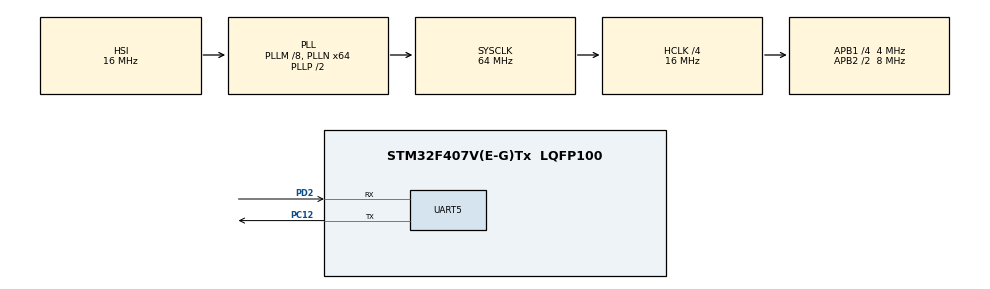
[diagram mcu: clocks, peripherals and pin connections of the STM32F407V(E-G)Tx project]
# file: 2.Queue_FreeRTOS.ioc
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Mcu.Family=STM32F4
Mcu.Name=STM32F407V(E-G)Tx
Mcu.Package=LQFP100
NVIC.PriorityGroup=NVIC_PRIORITYGROUP_4
NVIC.TIM6_DAC_IRQn=true\:15\:0\:false\:false\:true\:false\:true\:true
NVIC.TimeBase=TIM6_DAC_IRQn
NVIC.TimeBaseIP=TIM6
PA13.Mode=Serial_Wire
PA13.Signal=SYS_JTMS-SWDIO
PA14.Mode=Serial_Wire
PA14.Signal=SYS_JTCK-SWCLK
PC12.Mode=Asynchronous
PC12.Signal=UART5_TX
PD2.Mode=Asynchronous
PD2.Signal=UART5_RX
ProjectManager.HeapSize=0x200
ProjectManager.StackSize=0x400
ProjectManager.TargetToolchain=STM32CubeIDE
RCC.48MHZClocksFreq_Value=18285714.285714287
RCC.AHBCLKDivider=RCC_SYSCLK_DIV4
RCC.AHBFreq_Value=16000000
RCC.APB1CLKDivider=RCC_HCLK_DIV4
RCC.APB1Freq_Value=4000000
RCC.APB1TimFreq_Value=8000000
RCC.APB2CLKDivider=RCC_HCLK_DIV2
RCC.APB2Freq_Value=8000000
RCC.APB2TimFreq_Value=16000000
RCC.CortexFreq_Value=16000000
RCC.HCLKFreq_Value=16000000
RCC.HSE_VALUE=8000000
RCC.HSI_VALUE=16000000
RCC.LSE_VALUE=32768
RCC.PLLM=8
RCC.PLLN=64
RCC.PLLQ=7
RCC.SYSCLKFreq_VALUE=64000000
RCC.SYSCLKSource=RCC_SYSCLKSOURCE_PLLCLK
RCC.VCOOutputFreq_Value=128000000
UART5.VirtualMode=Asynchronous
VP_SYS_VS_tim6.Mode=TIM6
board=STM32F407G-DISC1

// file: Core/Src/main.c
/* USER CODE BEGIN Header */
/**
 ******************************************************************************
 * @file           : main.c
 * @brief          : Main program body
 ******************************************************************************
 * @attention
 *
 * Copyright (c) 2024 STMicroelectronics.
 * All rights reserved.
 *
 * This software is licensed under terms that can be found in the LICENSE file
 * in the root directory of this software component.
 * If no LICENSE file comes with this software, it is provided AS-IS.
 *
 ******************************************************************************
 */
/* USER CODE END Header */
#include "main.h"

/* USER CODE BEGIN Includes */

#include "FreeRTOS.h"
#include "task.h"
#include "queue.h"
#include<stdio.h>

/* USER CODE END Includes */

UART_HandleTypeDef huart5;

/* USER CODE BEGIN PV */

TaskHandle_t sender_handle, receiver_handle;
QueueHandle_t messageQueue;
QueueHandle_t numberQueue;

/* USER CODE END PV */

void SystemClock_Config(void);
static void MX_GPIO_Init(void);
static void MX_UART5_Init(void);
/* USER CODE BEGIN PFP */

void SenderTask(void *pvParameters);
void ReceiverTask(void *pvParameters);
int uart5_write(int ch);

/* USER CODE END PFP */

/* USER CODE BEGIN 0 */

// Sender task: sends messages to the queue
void SenderTask(void *pvParameters) {
	char *message1 = "Hello from Sender 1!\r\n";
	char *message2 = "Hello from Sender 2!\r\n";
	uint32_t data = 120;

	while (1) {
		xQueueSend(messageQueue, &message1, portMAX_DELAY); // Send message 1
		vTaskDelay(pdMS_TO_TICKS(500));                    // Wait 1 second

		xQueueSend(messageQueue, &message2, portMAX_DELAY); // Send message 2
		vTaskDelay(pdMS_TO_TICKS(500));                    // Wait 1 second

		xQueueSend(numberQueue, &data, portMAX_DELAY); // Send message 1
		vTaskDelay(pdMS_TO_TICKS(500));                    // Wait 1 second
	}
}

// Receiver task: receives messages from the queue and prints them using printf
void ReceiverTask(void *pvParameters) {
	char *receivedMessage;
	uint32_t data;
	while (1) {
		if (xQueueReceive(messageQueue, &receivedMessage,
				portMAX_DELAY) == pdPASS) {
			printf("%s", receivedMessage);  // Print received message via printf
		}

		if (xQueueReceive(numberQueue, &data, portMAX_DELAY) == pdPASS) {
			printf("Received : %lu\r\n", data); // Print received message via printf
		}
	}
}

/* USER CODE END 0 */

int main(void)
{

  /* MCU Configuration--------------------------------------------------------*/

  /* Reset of all peripherals, Initializes the Flash interface and the Systick. */
  HAL_Init();

  /* Configure the system clock */
  SystemClock_Config();

  /* Initialize all configured peripherals */
  MX_GPIO_Init();
  MX_UART5_Init();
  /* USER CODE BEGIN 2 */

	/// Create the queue (with space for 5 char* pointers)
	messageQueue = xQueueCreate(5, sizeof(char*));
	numberQueue = xQueueCreate(5, sizeof(uint32_t));

	if (messageQueue == NULL) {
		// Queue creation failed
		printf("Message Queue creation failed!\r\n");
		while (1){}
	}

	if (numberQueue == NULL) {
		// Queue creation failed
		printf("Number Queue creation failed!\r\n");
		while (1){}
	}

	// Create the sender and receiver tasks
	xTaskCreate(SenderTask, "SenderTask", 200, NULL, 1, NULL);
	xTaskCreate(ReceiverTask, "ReceiverTask", 200, NULL, 1, NULL);

	// Start the scheduler
	vTaskStartScheduler();

  /* USER CODE END 2 */

  /* Infinite loop */
	while (1) {

	}
}

void SystemClock_Config(void)
{
  RCC_OscInitTypeDef RCC_OscInitStruct = {0};
  RCC_ClkInitTypeDef RCC_ClkInitStruct = {0};

  /** Configure the main internal regulator output voltage
  */
  __HAL_RCC_PWR_CLK_ENABLE();
  __HAL_PWR_VOLTAGESCALING_CONFIG(PWR_REGULATOR_VOLTAGE_SCALE1);

  /** Initializes the RCC Oscillators according to the specified parameters
  * in the RCC_OscInitTypeDef structure.
  */
  RCC_OscInitStruct.OscillatorType = RCC_OSCILLATORTYPE_HSI;
  RCC_OscInitStruct.HSIState = RCC_HSI_ON;
  RCC_OscInitStruct.HSICalibrationValue = RCC_HSICALIBRATION_DEFAULT;
  RCC_OscInitStruct.PLL.PLLState = RCC_PLL_ON;
  RCC_OscInitStruct.PLL.PLLSource = RCC_PLLSOURCE_HSI;
  RCC_OscInitStruct.PLL.PLLM = 8;
  RCC_OscInitStruct.PLL.PLLN = 64;
  RCC_OscInitStruct.PLL.PLLP = RCC_PLLP_DIV2;
  RCC_OscInitStruct.PLL.PLLQ = 7;
  if (HAL_RCC_OscConfig(&RCC_OscInitStruct) != HAL_OK)
  {
    Error_Handler();
  }

  /** Initializes the CPU, AHB and APB buses clocks
  */
  RCC_ClkInitStruct.ClockType = RCC_CLOCKTYPE_HCLK|RCC_CLOCKTYPE_SYSCLK
                              |RCC_CLOCKTYPE_PCLK1|RCC_CLOCKTYPE_PCLK2;
  RCC_ClkInitStruct.SYSCLKSource = RCC_SYSCLKSOURCE_PLLCLK;
  RCC_ClkInitStruct.AHBCLKDivider = RCC_SYSCLK_DIV4;
  RCC_ClkInitStruct.APB1CLKDivider = RCC_HCLK_DIV4;
  RCC_ClkInitStruct.APB2CLKDivider = RCC_HCLK_DIV2;

  if (HAL_RCC_ClockConfig(&RCC_ClkInitStruct, FLASH_LATENCY_0) != HAL_OK)
  {
    Error_Handler();
  }
}

static void MX_UART5_Init(void)
{

  huart5.Instance = UART5;
  huart5.Init.BaudRate = 115200;
  huart5.Init.WordLength = UART_WORDLENGTH_8B;
  huart5.Init.StopBits = UART_STOPBITS_1;
  huart5.Init.Parity = UART_PARITY_NONE;
  huart5.Init.Mode = UART_MODE_TX_RX;
  huart5.Init.HwFlowCtl = UART_HWCONTROL_NONE;
  huart5.Init.OverSampling = UART_OVERSAMPLING_16;
  if (HAL_UART_Init(&huart5) != HAL_OK)
  {
    Error_Handler();
  }

}

static void MX_GPIO_Init(void)
{

  /* GPIO Ports Clock Enable */
  __HAL_RCC_GPIOA_CLK_ENABLE();
  __HAL_RCC_GPIOC_CLK_ENABLE();
  __HAL_RCC_GPIOD_CLK_ENABLE();

}

/* USER CODE BEGIN 4 */

int __io_putchar(int ch) {
	uint8_t c = ch;
	HAL_UART_Transmit(&huart5, &c, 1, HAL_MAX_DELAY);
	return ch;
}

/* USER CODE END 4 */

void HAL_TIM_PeriodElapsedCallback(TIM_HandleTypeDef *htim)
{
  if (htim->Instance == TIM6) {
    HAL_IncTick();
  }
}

void Error_Handler(void)
{
	__disable_irq();
	while (1) {
	}
}
